# LPC844 register map
Vendor: nxp.com; File version: 1.0
CPU: CM0PLUS r0p0, little endian, no MPU, no FPU, VTOR, 2 interrupt priority bits
Registers are 32-bit, read-write, reset 0x0 unless marked. A register's access mark holds for its fields unless they carry their own. Offsets are from the block's base; [hi:lo] are bit positions.

## WWDT — LPC84x Windowed Watchdog Timer (WWDT)
Base 0x40000000
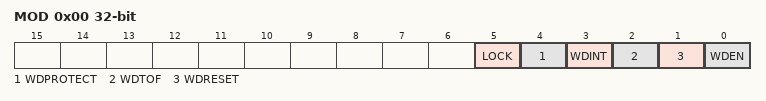
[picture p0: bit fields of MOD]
0x00 MOD — Watchdog mode register. This register contains the basic mode and status of the Watchdog Timer.
  [5] LOCK — Once this bit is set to one and a watchdog feed is performed, disabling or powering down the watchdog oscillator is prevented by hardware. This bit can be set once by software and is only cleared by any reset.
  [4] WDPROTECT — Watchdog update mode. This bit can be set once by software and is only cleared by a reset.
    0=FLEXIBLE (Flexible. The watchdog time-out value (TC) can be changed at any time.); 1=THRESHOLD (Threshold. The watchdog time-out value (TC) can be changed only after the counter is below the value of WDWARNINT and WDWINDOW.)
  [3] WDINT — Warning interrupt flag. Set when the timer is at or below the value in WDWARNINT. Cleared by software writing a 1 to this bit position. Note that this bit cannot be cleared while the WARNINT value is equal to the value of the TV register. This can occur if the value of WARNINT is 0 and the WDRESET bit is 0 when TV decrements to 0.
  [2] WDTOF — Watchdog time-out flag. Set when the watchdog timer times out, by a feed error, or by events associated with WDPROTECT. Cleared by software writing a 0 to this bit position. Causes a chip reset if WDRESET = 1.
  [1] WDRESET — Watchdog reset enable bit. Once this bit has been written with a 1 it cannot be re-written with a 0.
    0=INTERRUPT (Interrupt. A watchdog time-out will not cause a chip reset.); 1=RESET (Reset. A watchdog time-out will cause a chip reset.)
  [0] WDEN — Watchdog enable bit. Once this bit is set to one and a watchdog feed is performed, the watchdog timer will run permanently.
    0=STOP (Stop. The watchdog timer is stopped.); 1=RUN (Run. The watchdog timer is running.)
0x04 TC reset 0xFF — Watchdog timer constant register. This 24-bit register determines the time-out value.
  [23:0] COUNT — Watchdog time-out value.
0x08 FEED wo reset not defined — Watchdog feed sequence register. Writing 0xAA followed by 0x55 to this register reloads the Watchdog timer with the value contained in TC.
  [7:0] FEED — Feed value should be 0xAA followed by 0x55.
0x0C TV ro reset 0xFF — Watchdog timer value register. This 24-bit register reads out the current value of the Watchdog timer.
  [23:0] COUNT — Counter timer value.
0x14 WARNINT — Watchdog Warning Interrupt compare value.
  [9:0] WARNINT — Watchdog warning interrupt compare value.
0x18 WINDOW reset 0xFFFFFF — Watchdog Window compare value.
  [23:0] WINDOW — Watchdog window value.

## WKT — LPC84x Wake Up Timer(WKT)
Base 0x40008000
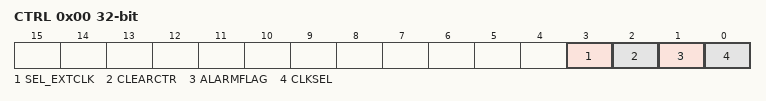
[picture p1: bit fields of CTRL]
0x00 CTRL — Self wake-up timer control register.
  [3] SEL_EXTCLK — Select external or internal clock source for the self wake-up timer. The internal clock source is selected by the CLKSEL bit in this register if SET_EXTCLK is set to internal.
    0=INTERNAL (Internal. The clock source is the internal clock selected by the CLKSEL bit.); 1=EXTERNAL (External. The self wake-up timer uses the external WKTCLKIN pin.)
  [2] CLEARCTR — Clears the self wake-up timer.
    0=NO_EFFECT (No effect. Reading this bit always returns 0.); 1=CLEAR_THE_COUNTER (Clear the counter. Counting is halted until a new count value is loaded.)
  [1] ALARMFLAG — Wake-up or alarm timer flag.
    0=NO_TIME_OUT (No time-out. The self wake-up timer has not timed out. Writing a 0 to has no effect.); 1=TIME_OUT (Time-out. The self wake-up timer has timed out. This flag generates an interrupt request which can wake up the part from any reduced power mode including Deep power-down if the clock source is the low power oscillator. Writing a 1 clears this status bit.)
  [0] CLKSEL — Select the self wake-up timer clock source. Remark: This bit only has an effect if the SEL_EXTCLK bit is not set.
    0=DIVIDED_IRC_CLOCK (Divided IRC clock. This clock runs at 750 kHz and provides time-out periods of up to approximately 95 minutes in 1.33 us increments. Remark: This clock is not available in not available in Deep-sleep, power-down, deep power-down modes. Do not select this option if the timer is to be used to wake up from one of these modes.); 1=LOW_POWER_CLOCK (This is the (nominally) 10 kHz clock and provides time-out periods of up to approximately 119 hours in 100 us increments. The accuracy of this clock is limited to +/- 40 % over temperature and processing. Remark: This clock is available in all power modes. Prior to use, the low-power oscillator must be enabled. The oscillator must also be set to remain active in Deep power-down if needed.)
0x0C COUNT reset not defined — Counter register.
  [31:0] VALUE — A write to this register pre-loads start count value into the timer and starts the count-down sequence. A read reflects the current value of the timer.
